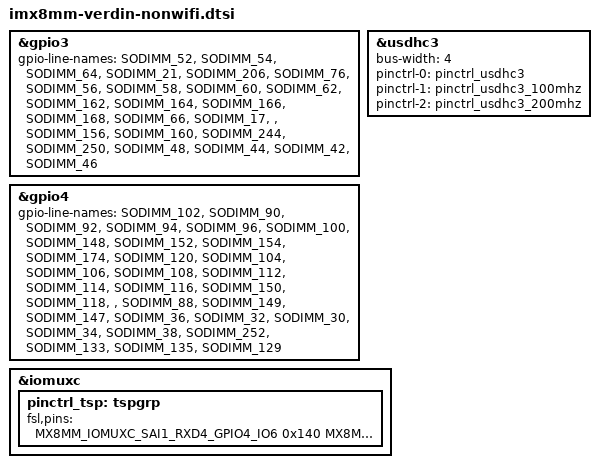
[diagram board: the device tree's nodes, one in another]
// SPDX-License-Identifier: GPL-2.0+ OR MIT
/*
 * Copyright 2020 Toradex
 */

#include "imx8mm-verdin.dtsi"

&gpio3 {
	gpio-line-names = "SODIMM_52",
			  "SODIMM_54",
			  "SODIMM_64",
			  "SODIMM_21",
			  "SODIMM_206",
			  "SODIMM_76",
			  "SODIMM_56",
			  "SODIMM_58",
			  "SODIMM_60",
			  "SODIMM_62",
			  "SODIMM_162",
			  "SODIMM_164",
			  "SODIMM_166",
			  "SODIMM_168",
			  "SODIMM_66",
			  "SODIMM_17",
			  "",
			  "SODIMM_156",
			  "SODIMM_160",
			  "SODIMM_244",
			  "SODIMM_250",
			  "SODIMM_48",
			  "SODIMM_44",
			  "SODIMM_42",
			  "SODIMM_46";
};

&gpio4 {
	gpio-line-names = "SODIMM_102",
			  "SODIMM_90",
			  "SODIMM_92",
			  "SODIMM_94",
			  "SODIMM_96",
			  "SODIMM_100",
			  "SODIMM_148",
			  "SODIMM_152",
			  "SODIMM_154",
			  "SODIMM_174",
			  "SODIMM_120",
			  "SODIMM_104",
			  "SODIMM_106",
			  "SODIMM_108",
			  "SODIMM_112",
			  "SODIMM_114",
			  "SODIMM_116",
			  "SODIMM_150",
			  "SODIMM_118",
			  "",
			  "SODIMM_88",
			  "SODIMM_149",
			  "SODIMM_147",
			  "SODIMM_36",
			  "SODIMM_32",
			  "SODIMM_30",
			  "SODIMM_34",
			  "SODIMM_38",
			  "SODIMM_252",
			  "SODIMM_133",
			  "SODIMM_135",
			  "SODIMM_129";
};

&usdhc3 {
	bus-width = <4>;
	pinctrl-names = "default", "state_100mhz", "state_200mhz";
	pinctrl-0 = <&pinctrl_usdhc3>;
	pinctrl-1 = <&pinctrl_usdhc3_100mhz>;
	pinctrl-2 = <&pinctrl_usdhc3_200mhz>;
};

&iomuxc {
	pinctrl_tsp: tspgrp {
		fsl,pins = <
			MX8MM_IOMUXC_SAI1_RXD4_GPIO4_IO6			0x140		/* SODIMM 148 */
			MX8MM_IOMUXC_SAI1_RXD5_GPIO4_IO7			0x140		/* SODIMM 152 */
			MX8MM_IOMUXC_SAI1_RXD6_GPIO4_IO8			0x140		/* SODIMM 154 */
			MX8MM_IOMUXC_SAI1_RXD7_GPIO4_IO9			0x140		/* SODIMM 179 */
			MX8MM_IOMUXC_SAI1_TXD5_GPIO4_IO17			0x140		/* SODIMM 150 */
		>;
	};
};
